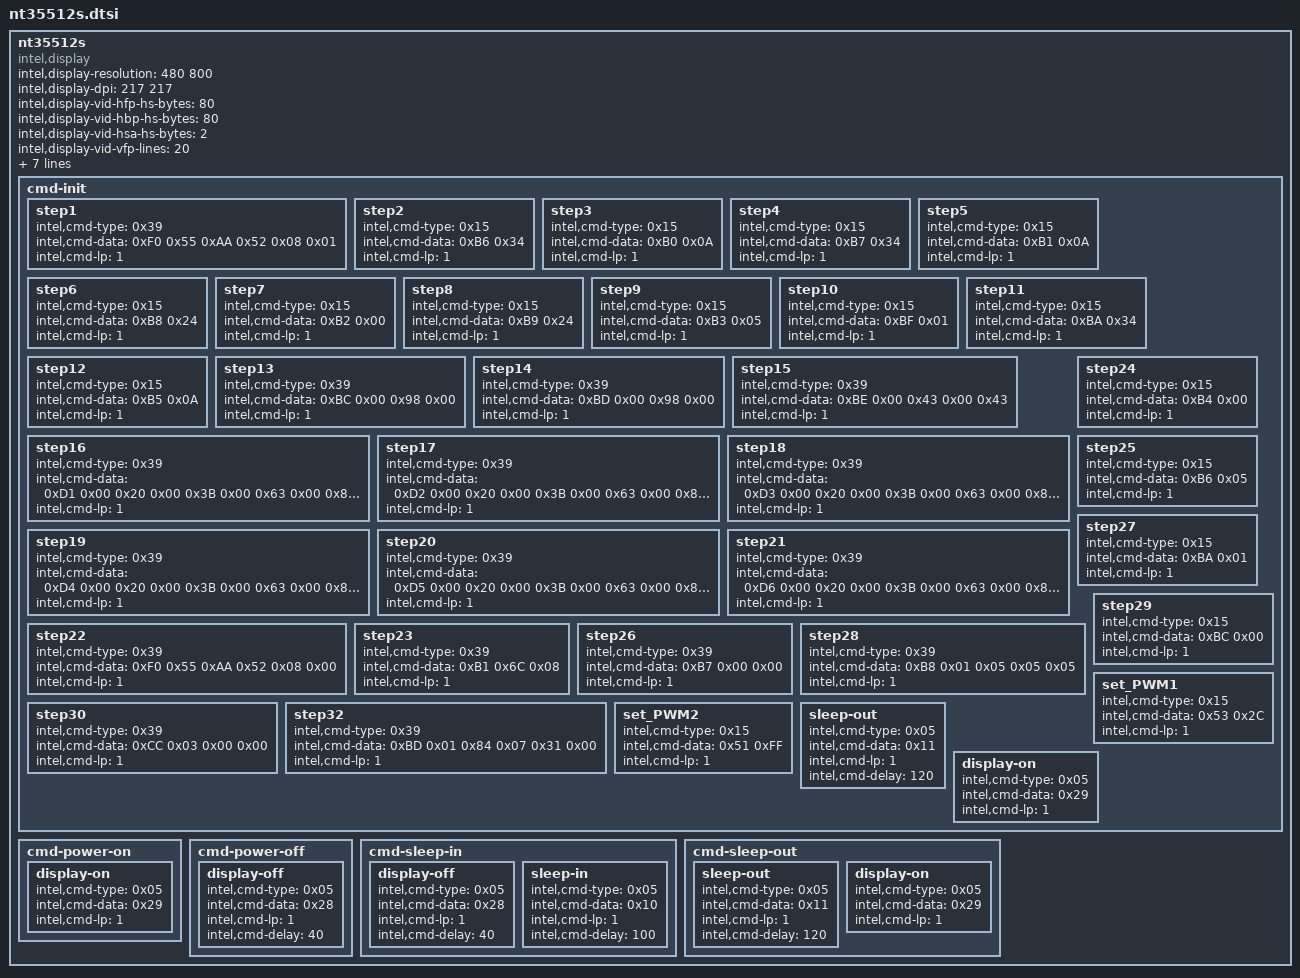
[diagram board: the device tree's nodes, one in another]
	nt35512s {
		compatible = "intel,display";
		intel,display-resolution= <480 800>;
		intel,display-dpi= <217 217>;

		/* MIPI-DSI video mode settings */

		intel,display-vid-hfp-hs-bytes = <80>;
		intel,display-vid-hbp-hs-bytes = <80>;
		intel,display-vid-hsa-hs-bytes = <2>;

		intel,display-vid-vfp-lines = <20>;
		intel,display-vid-vbp-lines = <20>;
		intel,display-vid-vsa-lines = <2>;

		intel,display-vid-mode = "pulses";
		intel,display-vid-id = <0>;
		intel,display-vid-pixel = "24packed";
		intel,display-vid-fill_buf_to = <0x1F>;

		intel,display-reset = <1 1 0 5 1 50>;

		cmd-init {
			step1 {
				intel,cmd-type = <0x39>;
				intel,cmd-data = <0xF0 0x55 0xAA 0x52 0x08 0x01>;
				intel,cmd-lp = <1>;
			};
			step2 {
				intel,cmd-type = <0x15>;
				intel,cmd-data = <0xB6 0x34>;
				intel,cmd-lp = <1>;
			};
			step3 {
				intel,cmd-type = <0x15>;
				intel,cmd-data = <0xB0 0x0A>;
				intel,cmd-lp = <1>;
			};
			step4 {
				intel,cmd-type = <0x15>;
				intel,cmd-data = <0xB7 0x34>;
				intel,cmd-lp = <1>;
			};
			step5 {
				intel,cmd-type = <0x15>;
				intel,cmd-data = <0xB1 0x0A>;
				intel,cmd-lp = <1>;
			};
			step6 {
				intel,cmd-type = <0x15>;
				intel,cmd-data = <0xB8 0x24>;
				intel,cmd-lp = <1>;
			};
			step7 {
				intel,cmd-type = <0x15>;
				intel,cmd-data = <0xB2 0x00>;
				intel,cmd-lp = <1>;
			};
			step8 {
				intel,cmd-type = <0x15>;
				intel,cmd-data = <0xB9 0x24>;
				intel,cmd-lp = <1>;
			};
			step9 {
				intel,cmd-type = <0x15>;
				intel,cmd-data = <0xB3 0x05>;
				intel,cmd-lp = <1>;
			};
			step10 {
				intel,cmd-type = <0x15>;
				intel,cmd-data = <0xBF 0x01>;
				intel,cmd-lp = <1>;
			};
			step11 {
				intel,cmd-type = <0x15>;
				intel,cmd-data = <0xBA 0x34>;
				intel,cmd-lp = <1>;
			};
			step12 {
				intel,cmd-type = <0x15>;
				intel,cmd-data = <0xB5 0x0A>;
				intel,cmd-lp = <1>;
			};
			step13 {
				intel,cmd-type = <0x39>;
				intel,cmd-data = <0xBC 0x00 0x98 0x00>;
				intel,cmd-lp = <1>;
			};
			step14 {
				intel,cmd-type = <0x39>;
				intel,cmd-data = <0xBD 0x00 0x98 0x00>;
				intel,cmd-lp = <1>;
			};
			step15 {
				intel,cmd-type = <0x39>;
				intel,cmd-data = <0xBE 0x00 0x43 0x00 0x43>;
				intel,cmd-lp = <1>;
			};
			step16 {
				intel,cmd-type = <0x39>;
				intel,cmd-data = <0xD1 0x00 0x20 0x00 0x3B 0x00 0x63 0x00 0x81 0x00 0x94 0x00 0xB9 0x00 0xDA 0x01 0x0C 0x01 0x34 0x01 0x71 0x01 0xA1 0x01 0xEE 0x02 0x2D 0x02 0x2F 0x02 0x68 0x02 0xA5 0x02 0xCB 0x02 0xFE 0x03 0x20 0x03 0x50 0x03 0x73 0x03 0x9E 0x03 0xAE 0x03 0xD6 0x03 0xE8 0x03 0xFF>;
				intel,cmd-lp = <1>;
			};
			step17 {
				intel,cmd-type = <0x39>;
				intel,cmd-data = <0xD2 0x00 0x20 0x00 0x3B 0x00 0x63 0x00 0x81 0x00 0x94 0x00 0xB9 0x00 0xDA 0x01 0x0C 0x01 0x34 0x01 0x71 0x01 0xA1 0x01 0xEE 0x02 0x2D 0x02 0x2F 0x02 0x68 0x02 0xA5 0x02 0xCB 0x02 0xFE 0x03 0x20 0x03 0x50 0x03 0x73 0x03 0x9E 0x03 0xAE 0x03 0xD6 0x03 0xE8 0x03 0xFF>;
				intel,cmd-lp = <1>;
			};
			step18 {
				intel,cmd-type = <0x39>;
				intel,cmd-data = <0xD3 0x00 0x20 0x00 0x3B 0x00 0x63 0x00 0x81 0x00 0x94 0x00 0xB9 0x00 0xDA 0x01 0x0C 0x01 0x34 0x01 0x71 0x01 0xA1 0x01 0xEE 0x02 0x2D 0x02 0x2F 0x02 0x68 0x02 0xA5 0x02 0xCB 0x02 0xFE 0x03 0x20 0x03 0x50 0x03 0x73 0x03 0x9E 0x03 0xAE 0x03 0xD6 0x03 0xE8 0x03 0xFF>;
				intel,cmd-lp = <1>;
			};
			step19 {
				intel,cmd-type = <0x39>;
				intel,cmd-data = <0xD4 0x00 0x20 0x00 0x3B 0x00 0x63 0x00 0x81 0x00 0x94 0x00 0xB9 0x00 0xDA 0x01 0x0C 0x01 0x34 0x01 0x71 0x01 0xA1 0x01 0xEE 0x02 0x2D 0x02 0x2F 0x02 0x68 0x02 0xA5 0x02 0xCB 0x02 0xFE 0x03 0x20 0x03 0x50 0x03 0x73 0x03 0x9E 0x03 0xAE 0x03 0xD6 0x03 0xE8 0x03 0xFF>;
				intel,cmd-lp = <1>;
			};
			step20 {
				intel,cmd-type = <0x39>;
				intel,cmd-data = <0xD5 0x00 0x20 0x00 0x3B 0x00 0x63 0x00 0x81 0x00 0x94 0x00 0xB9 0x00 0xDA 0x01 0x0C 0x01 0x34 0x01 0x71 0x01 0xA1 0x01 0xEE 0x02 0x2D 0x02 0x2F 0x02 0x68 0x02 0xA5 0x02 0xCB 0x02 0xFE 0x03 0x20 0x03 0x50 0x03 0x73 0x03 0x9E 0x03 0xAE 0x03 0xD6 0x03 0xE8 0x03 0xFF>;
				intel,cmd-lp = <1>;
			};
			step21 {
				intel,cmd-type = <0x39>;
				intel,cmd-data = <0xD6 0x00 0x20 0x00 0x3B 0x00 0x63 0x00 0x81 0x00 0x94 0x00 0xB9 0x00 0xDA 0x01 0x0C 0x01 0x34 0x01 0x71 0x01 0xA1 0x01 0xEE 0x02 0x2D 0x02 0x2F 0x02 0x68 0x02 0xA5 0x02 0xCB 0x02 0xFE 0x03 0x20 0x03 0x50 0x03 0x73 0x03 0x9E 0x03 0xAE 0x03 0xD6 0x03 0xE8 0x03 0xFF>;
				intel,cmd-lp = <1>;
			};

			step22 {
				intel,cmd-type = <0x39>;
				intel,cmd-data = <0xF0 0x55 0xAA 0x52 0x08 0x00>;
				intel,cmd-lp = <1>;
			};
			step23 {
				intel,cmd-type = <0x39>;
				intel,cmd-data = <0xB1 0x6C 0x08>;
				intel,cmd-lp = <1>;
			};
			step24 {
				intel,cmd-type = <0x15>;
				intel,cmd-data = <0xB4 0x00>;
				intel,cmd-lp = <1>;
			};
			step25 {
				intel,cmd-type = <0x15>;
				intel,cmd-data = <0xB6 0x05>;
				intel,cmd-lp = <1>;
			};
			step26 {
				intel,cmd-type = <0x39>;
				intel,cmd-data = <0xB7 0x00 0x00>;
				intel,cmd-lp = <1>;
			};
			step27 {
				intel,cmd-type = <0x15>;
				intel,cmd-data = <0xBA 0x01>;
				intel,cmd-lp = <1>;
			};
			step28 {
				intel,cmd-type = <0x39>;
				intel,cmd-data = <0xB8 0x01 0x05 0x05 0x05>;
				intel,cmd-lp = <1>;
			};
			step29 {
				intel,cmd-type = <0x15>;
				intel,cmd-data = <0xBC 0x00>;
				intel,cmd-lp = <1>;
			};
			step30 {
				intel,cmd-type = <0x39>;
				intel,cmd-data = <0xCC 0x03 0x00 0x00>;
				intel,cmd-lp = <1>;
			};
			step32 {
				intel,cmd-type = <0x39>;
				intel,cmd-data = <0xBD 0x01 0x84 0x07 0x31 0x00>;
				intel,cmd-lp = <1>;
			};
			set_PWM1 {
				intel,cmd-type = <0x15>;
				intel,cmd-data = <0x53 0x2C>;
				intel,cmd-lp = <1>;
			};
			set_PWM2 {
				intel,cmd-type = <0x15>;
				intel,cmd-data = <0x51 0xFF>;
				intel,cmd-lp = <1>;
			};
			sleep-out {
				intel,cmd-type = <0x05>;
				intel,cmd-data = <0x11>;
				intel,cmd-lp = <1>;
				intel,cmd-delay = <120>;
			};
			display-on{
				intel,cmd-type = <0x05>;
				intel,cmd-data = <0x29>;
				intel,cmd-lp = <1>;
			};
		};

		cmd-power-on {
			display-on{
				intel,cmd-type = <0x05>;
				intel,cmd-data = <0x29>;
				intel,cmd-lp = <1>;
			};
		};

		cmd-power-off {
			display-off{
				intel,cmd-type = <0x05>;
				intel,cmd-data = <0x28>;
				intel,cmd-lp = <1>;
				intel,cmd-delay = <40>;
			};
		};

		cmd-sleep-in {
			display-off{
				intel,cmd-type = <0x05>;
				intel,cmd-data = <0x28>;
				intel,cmd-lp = <1>;
				intel,cmd-delay = <40>;
			};
			sleep-in{
				intel,cmd-type = <0x05>;
				intel,cmd-data = <0x10>;
				intel,cmd-lp = <1>;
				intel,cmd-delay = <100>;
			};
		};

		cmd-sleep-out {
			sleep-out{
				intel,cmd-type = <0x05>;
				intel,cmd-data = <0x11>;
				intel,cmd-lp = <1>;
				intel,cmd-delay = <120>;
			};
			display-on{
				intel,cmd-type = <0x05>;
				intel,cmd-data = <0x29>;
				intel,cmd-lp = <1>;
			};
		};
	};
